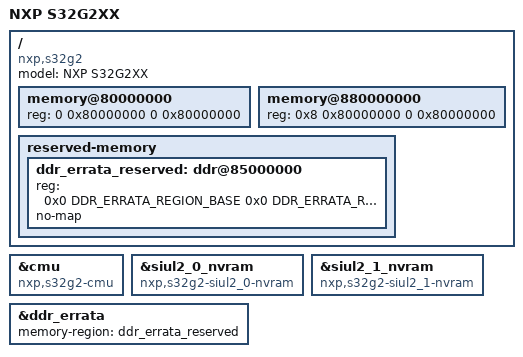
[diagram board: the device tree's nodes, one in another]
// SPDX-License-Identifier: GPL-2.0+
/*
 * Copyright 2021-2022 NXP
 *
 * This program is free software; you can redistribute it and/or modify
 * it under the terms of the GNU General Public License as published by
 * the Free Software Foundation; either version 2 of the License, or
 * (at your option) any later version.
 */

#include <dt-bindings/ddr-errata/s32-ddr-errata.h>
#include "s32g.dtsi"
/ {
	model = "NXP S32G2XX";
	compatible = "nxp,s32g2";

	memory@80000000 {
		device_type = "memory";
		reg = <0 0x80000000 0 0x80000000>;
	};

	memory@880000000 {
		device_type = "memory";
		reg = <0x8 0x80000000 0 0x80000000>;
	};

	reserved-memory {
		ddr_errata_reserved: ddr@85000000 {
			reg = <0x0 DDR_ERRATA_REGION_BASE
				0x0 DDR_ERRATA_REGION_SIZE>; /* 4 KB */
			no-map;
		};
	};
};

&cmu {
	compatible = "nxp,s32g2-cmu";
};

&siul2_0_nvram {
	compatible = "nxp,s32g2-siul2_0-nvram";
};

&siul2_1_nvram {
	compatible = "nxp,s32g2-siul2_1-nvram";
};

&ddr_errata {
	memory-region = <&ddr_errata_reserved>;
	status = "okay";
};
